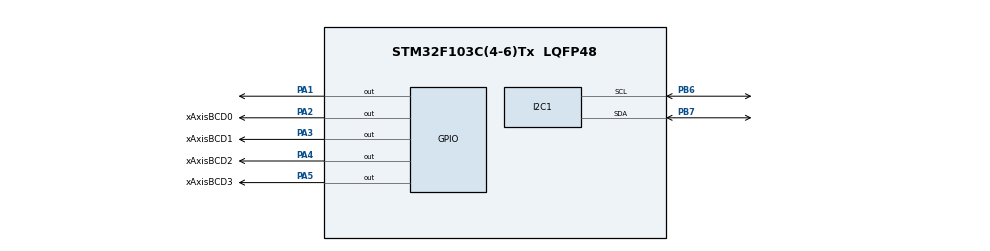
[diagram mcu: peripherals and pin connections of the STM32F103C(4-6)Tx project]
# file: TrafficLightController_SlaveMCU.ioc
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Dma.I2C1_RX.0.Direction=DMA_PERIPH_TO_MEMORY
Dma.I2C1_RX.0.Instance=DMA1_Channel7
Dma.I2C1_RX.0.MemDataAlignment=DMA_MDATAALIGN_BYTE
Dma.I2C1_RX.0.MemInc=DMA_MINC_ENABLE
Dma.I2C1_RX.0.Mode=DMA_NORMAL
Dma.I2C1_RX.0.PeriphDataAlignment=DMA_PDATAALIGN_BYTE
Dma.I2C1_RX.0.PeriphInc=DMA_PINC_DISABLE
Dma.I2C1_RX.0.Priority=DMA_PRIORITY_LOW
Dma.I2C1_TX.1.Direction=DMA_MEMORY_TO_PERIPH
Dma.I2C1_TX.1.Instance=DMA1_Channel6
Dma.I2C1_TX.1.MemDataAlignment=DMA_MDATAALIGN_BYTE
Dma.I2C1_TX.1.MemInc=DMA_MINC_ENABLE
Dma.I2C1_TX.1.Mode=DMA_NORMAL
Dma.I2C1_TX.1.PeriphDataAlignment=DMA_PDATAALIGN_BYTE
Dma.I2C1_TX.1.PeriphInc=DMA_PINC_DISABLE
Dma.I2C1_TX.1.Priority=DMA_PRIORITY_LOW
Dma.Request0=I2C1_RX
Dma.Request1=I2C1_TX
Mcu.Family=STM32F1
Mcu.Name=STM32F103C(4-6)Tx
Mcu.Package=LQFP48
NVIC.DMA1_Channel6_IRQn=true\:0\:0\:false\:false\:true\:false\:true\:true
NVIC.DMA1_Channel7_IRQn=true\:0\:0\:false\:false\:true\:false\:true\:true
NVIC.I2C1_EV_IRQn=true\:0\:0\:false\:false\:true\:true\:true\:true
NVIC.PriorityGroup=NVIC_PRIORITYGROUP_4
PA1.Signal=GPIO_Output
PA2.GPIO_Label=xAxisBCD0
PA2.Signal=GPIO_Output
PA3.GPIO_Label=xAxisBCD1
PA3.Signal=GPIO_Output
PA4.GPIO_Label=xAxisBCD2
PA4.Signal=GPIO_Output
PA5.GPIO_Label=xAxisBCD3
PA5.Signal=GPIO_Output
PB6.GPIO_Pu=GPIO_PULLUP
PB6.Mode=I2C
PB6.Signal=I2C1_SCL
PB7.GPIO_Pu=GPIO_PULLUP
PB7.Mode=I2C
PB7.Signal=I2C1_SDA
ProjectManager.HeapSize=0x200
ProjectManager.StackSize=0x400
ProjectManager.TargetToolchain=STM32CubeIDE
RCC.APB1Freq_Value=8000000
RCC.APB2Freq_Value=8000000
board=custom

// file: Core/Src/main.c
/* USER CODE BEGIN Header */
/**
  ******************************************************************************
  * @file           : main.c
  * @brief          : Main program body
  ******************************************************************************
  * @attention
  *
  * Copyright (c) 2023 STMicroelectronics.
  * All rights reserved.
  *
  * This software is licensed under terms that can be found in the LICENSE file
  * in the root directory of this software component.
  * If no LICENSE file comes with this software, it is provided AS-IS.
  *
  ******************************************************************************
  */
/* USER CODE END Header */
#include "main.h"

I2C_HandleTypeDef hi2c1;
DMA_HandleTypeDef hdma_i2c1_rx;
DMA_HandleTypeDef hdma_i2c1_tx;

void SystemClock_Config(void);
static void MX_GPIO_Init(void);
static void MX_DMA_Init(void);
static void MX_I2C1_Init(void);

int main(void)
{

  /* MCU Configuration--------------------------------------------------------*/

  /* Reset of all peripherals, Initializes the Flash interface and the Systick. */
  HAL_Init();

  /* Configure the system clock */
  SystemClock_Config();

  /* Initialize all configured peripherals */
  MX_GPIO_Init();
  MX_DMA_Init();
  MX_I2C1_Init();
  /* USER CODE BEGIN 2 */
  HAL_GPIO_WritePin(GPIOA, xAxisBCD0_Pin, GPIO_PIN_RESET);
  HAL_GPIO_WritePin(GPIOA, xAxisBCD1_Pin, GPIO_PIN_SET);
  HAL_GPIO_WritePin(GPIOA, xAxisBCD2_Pin, GPIO_PIN_RESET);
  HAL_GPIO_WritePin(GPIOA, xAxisBCD3_Pin, GPIO_PIN_RESET);
  /* USER CODE END 2 */

  /* Infinite loop */
  /* USER CODE BEGIN WHILE */
  while (1)
  {
	  HAL_GPIO_TogglePin(GPIOA, GPIO_PIN_1);
	  HAL_Delay(100);
    /* USER CODE END WHILE */

  }
}

void SystemClock_Config(void)
{
  RCC_OscInitTypeDef RCC_OscInitStruct = {0};
  RCC_ClkInitTypeDef RCC_ClkInitStruct = {0};

  /** Initializes the RCC Oscillators according to the specified parameters
  * in the RCC_OscInitTypeDef structure.
  */
  RCC_OscInitStruct.OscillatorType = RCC_OSCILLATORTYPE_HSI;
  RCC_OscInitStruct.HSIState = RCC_HSI_ON;
  RCC_OscInitStruct.HSICalibrationValue = RCC_HSICALIBRATION_DEFAULT;
  RCC_OscInitStruct.PLL.PLLState = RCC_PLL_NONE;
  if (HAL_RCC_OscConfig(&RCC_OscInitStruct) != HAL_OK)
  {
    Error_Handler();
  }

  /** Initializes the CPU, AHB and APB buses clocks
  */
  RCC_ClkInitStruct.ClockType = RCC_CLOCKTYPE_HCLK|RCC_CLOCKTYPE_SYSCLK
                              |RCC_CLOCKTYPE_PCLK1|RCC_CLOCKTYPE_PCLK2;
  RCC_ClkInitStruct.SYSCLKSource = RCC_SYSCLKSOURCE_HSI;
  RCC_ClkInitStruct.AHBCLKDivider = RCC_SYSCLK_DIV1;
  RCC_ClkInitStruct.APB1CLKDivider = RCC_HCLK_DIV1;
  RCC_ClkInitStruct.APB2CLKDivider = RCC_HCLK_DIV1;

  if (HAL_RCC_ClockConfig(&RCC_ClkInitStruct, FLASH_LATENCY_0) != HAL_OK)
  {
    Error_Handler();
  }
}

static void MX_I2C1_Init(void)
{

  hi2c1.Instance = I2C1;
  hi2c1.Init.ClockSpeed = 100000;
  hi2c1.Init.DutyCycle = I2C_DUTYCYCLE_2;
  hi2c1.Init.OwnAddress1 = 0;
  hi2c1.Init.AddressingMode = I2C_ADDRESSINGMODE_7BIT;
  hi2c1.Init.DualAddressMode = I2C_DUALADDRESS_DISABLE;
  hi2c1.Init.OwnAddress2 = 0;
  hi2c1.Init.GeneralCallMode = I2C_GENERALCALL_DISABLE;
  hi2c1.Init.NoStretchMode = I2C_NOSTRETCH_DISABLE;
  if (HAL_I2C_Init(&hi2c1) != HAL_OK)
  {
    Error_Handler();
  }

}

static void MX_DMA_Init(void)
{

  /* DMA controller clock enable */
  __HAL_RCC_DMA1_CLK_ENABLE();

  /* DMA interrupt init */
  /* DMA1_Channel6_IRQn interrupt configuration */
  HAL_NVIC_SetPriority(DMA1_Channel6_IRQn, 0, 0);
  HAL_NVIC_EnableIRQ(DMA1_Channel6_IRQn);
  /* DMA1_Channel7_IRQn interrupt configuration */
  HAL_NVIC_SetPriority(DMA1_Channel7_IRQn, 0, 0);
  HAL_NVIC_EnableIRQ(DMA1_Channel7_IRQn);

}

static void MX_GPIO_Init(void)
{
  GPIO_InitTypeDef GPIO_InitStruct = {0};

  /* GPIO Ports Clock Enable */
  __HAL_RCC_GPIOA_CLK_ENABLE();
  __HAL_RCC_GPIOB_CLK_ENABLE();

  /*Configure GPIO pin Output Level */
  HAL_GPIO_WritePin(GPIOA, GPIO_PIN_1|xAxisBCD0_Pin|xAxisBCD1_Pin|xAxisBCD2_Pin
                          |xAxisBCD3_Pin, GPIO_PIN_RESET);

  /*Configure GPIO pins : PA1 xAxisBCD0_Pin xAxisBCD1_Pin xAxisBCD2_Pin
                           xAxisBCD3_Pin */
  GPIO_InitStruct.Pin = GPIO_PIN_1|xAxisBCD0_Pin|xAxisBCD1_Pin|xAxisBCD2_Pin
                          |xAxisBCD3_Pin;
  GPIO_InitStruct.Mode = GPIO_MODE_OUTPUT_PP;
  GPIO_InitStruct.Pull = GPIO_NOPULL;
  GPIO_InitStruct.Speed = GPIO_SPEED_FREQ_LOW;
  HAL_GPIO_Init(GPIOA, &GPIO_InitStruct);

}

void Error_Handler(void)
{
  __disable_irq();
  while (1)
  {
  }
}
